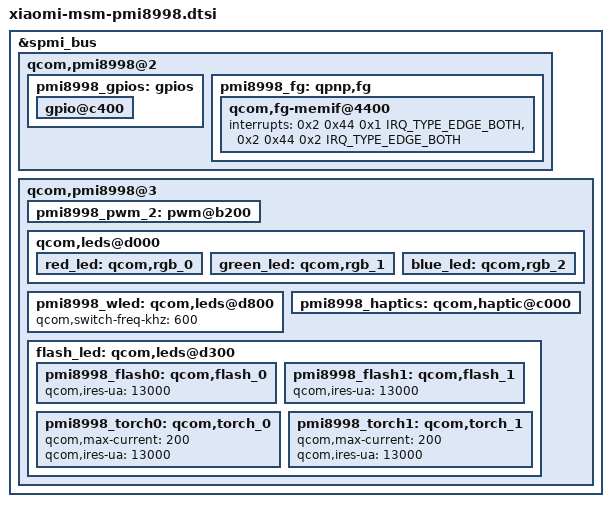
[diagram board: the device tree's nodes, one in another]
/* Copyright (c) 2016-2017, The Linux Foundation. All rights reserved.
 * Copyright (C) 2017 XiaoMi, Inc.
 *
 * This program is free software; you can redistribute it and/or modify
 * it under the terms of the GNU General Public License version 2 and
 * only version 2 as published by the Free Software Foundation.
 *
 * This program is distributed in the hope that it will be useful,
 * but WITHOUT ANY WARRANTY; without even the implied warranty of
 * MERCHANTABILITY or FITNESS FOR A PARTICULAR PURPOSE.  See the
 * GNU General Public License for more details.
 */

&spmi_bus {
	qcom,pmi8998@2 {
		pmi8998_gpios: gpios {
			gpio@c400 {
				status = "okay";
			};
		};

		pmi8998_fg: qpnp,fg {
			qcom,fg-memif@4400 {
				interrupts = <0x2 0x44 0x1 IRQ_TYPE_EDGE_BOTH>,
					     <0x2 0x44 0x2 IRQ_TYPE_EDGE_BOTH>;
				interrupt-names = "mem-xcp",
						  "dma-grant";
			};
		};
	};

	qcom,pmi8998@3 {
		pmi8998_pwm_2: pwm@b200 {
			status = "okay";
		};

		qcom,leds@d000 {
			red_led: qcom,rgb_0 {
				/delete-property/ linux,default-trigger;
			};
			green_led: qcom,rgb_1 {
				/delete-property/ linux,default-trigger;
			};

			blue_led: qcom,rgb_2 {
				/delete-property/ linux,default-trigger;
			};
		};

		pmi8998_wled: qcom,leds@d800 {
			qcom,switch-freq-khz = <600>;
			/delete-property/ qcom,en-ext-pfet-sc-pro;
		};

		pmi8998_haptics: qcom,haptic@c000 {
			/delete-property/ qcom,correct-lra-drive-freq;
		};

		flash_led: qcom,leds@d300 {
			pmi8998_flash0: qcom,flash_0 {
				qcom,ires-ua = <13000>;
			};

			pmi8998_flash1: qcom,flash_1 {
				qcom,ires-ua = <13000>;
			};

			pmi8998_torch0: qcom,torch_0 {
				qcom,max-current = <200>;
				qcom,ires-ua = <13000>;
			};

			pmi8998_torch1: qcom,torch_1 {
				qcom,max-current = <200>;
				qcom,ires-ua = <13000>;
			};
		};
	};
};
